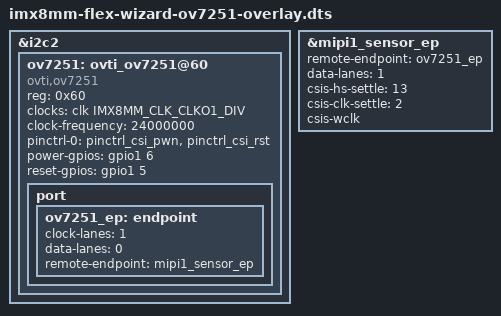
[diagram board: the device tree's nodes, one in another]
/dts-v1/;
/plugin/;

#include <dt-bindings/clock/imx8mm-clock.h>
#include <dt-bindings/gpio/gpio.h>

/ {
	fragment@0 {
		target = <&i2c2>;
		__overlay__ {
			#address-cells = <1>;
			#size-cells = <0>;
			status = "okay";

			ov7251: ovti_ov7251@60 {
				compatible = "ovti,ov7251";
				reg = <0x60>;

				clocks = <&clk IMX8MM_CLK_CLKO1_DIV>;
				clock-names = "xclk";
				clock-frequency = <24000000>;

				pinctrl-names = "default";
				pinctrl-0 = <&pinctrl_csi_pwn>, <&pinctrl_csi_rst>;

				power-gpios = <&gpio1 6 GPIO_ACTIVE_HIGH>;
				reset-gpios = <&gpio1 5 GPIO_ACTIVE_HIGH>;
				status = "okay";

				port {
					ov7251_ep: endpoint {
						clock-lanes = <1>;
						data-lanes = <0>;
						remote-endpoint = <&mipi1_sensor_ep>;
					};
				};
			};
		};
	};

	fragment@1 {
		target = <&mipi1_sensor_ep>;
		__overlay__ {
			remote-endpoint = <&ov7251_ep>;
			data-lanes = <1>;
			csis-hs-settle = <13>;
			csis-clk-settle = <2>;
			csis-wclk;
		};
	};
};
